# STM32U5F7 register map
File version: 1.1
CPU: CM33 r0p1, little endian, MPU, FPU, 4 interrupt priority bits
Registers are 32-bit, read-write, reset 0x0 unless marked. A register's access mark holds for its fields unless they carry their own. Offsets are from the block's base; [hi:lo] are bit positions.

## I2C1 — Inter-integrated circuit
Base 0x40005400
Same registers: I2C2 0x40005800, I2C4 0x40008400, I2C5 0x40009800, I2C6 0x40009C00, I2C3 0x46002800, SEC_I2C1 0x50005400, SEC_I2C2 0x50005800, SEC_I2C4 0x50008400, SEC_I2C5 0x50009800, SEC_I2C6 0x50009C00, SEC_I2C3 0x56002800
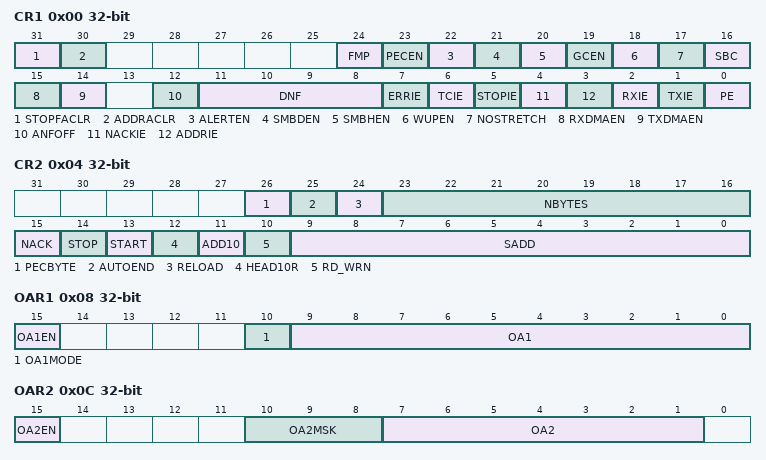
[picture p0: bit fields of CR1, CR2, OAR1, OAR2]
0x00 CR1 — Control register 1
  [31] STOPFACLR — STOP detection flag (STOPF) automatic clear
  [30] ADDRACLR — Address match flag (ADDR) automatic clear
  [24] FMP — Fast-mode Plus 20 mA drive enable
  [23] PECEN — PEC enable
  [22] ALERTEN — SMBUS alert enable
  [21] SMBDEN — SMBus Device Default address
  [20] SMBHEN — SMBus Host address enable
  [19] GCEN — General call enable
  [18] WUPEN — Wakeup from STOP enable
  [17] NOSTRETCH — Clock stretching disable
  [16] SBC — Slave byte control
  [15] RXDMAEN — DMA reception requests
  [14] TXDMAEN — DMA transmission requests
  [12] ANFOFF — Analog noise filter OFF
  [11:8] DNF — Digital noise filter
  [7] ERRIE — Error interrupts enable
  [6] TCIE — Transfer Complete interrupt
  [5] STOPIE — STOP detection Interrupt
  [4] NACKIE — Not acknowledge received interrupt
  [3] ADDRIE — Address match interrupt enable (slave
  [2] RXIE — RX Interrupt enable
  [1] TXIE — TX Interrupt enable
  [0] PE — Peripheral enable
0x04 CR2 — Control register 2
  [26] PECBYTE — Packet error checking byte
  [25] AUTOEND — Automatic end mode (master
  [24] RELOAD — NBYTES reload mode
  [23:16] NBYTES — Number of bytes
  [15] NACK — NACK generation (slave
  [14] STOP — Stop generation (master
  [13] START — Start generation
  [12] HEAD10R — 10-bit address header only read
  [11] ADD10 — 10-bit addressing mode (master
  [10] RD_WRN — Transfer direction (master
  [9:0] SADD — Slave address bit (master
0x08 OAR1 — Own address register 1
  [15] OA1EN — Own Address 1 enable
  [10] OA1MODE — Own Address 1 10-bit mode
  [9:0] OA1 — Interface address
0x0C OAR2 — Own address register 2
  [15] OA2EN — Own Address 2 enable
  [10:8] OA2MSK — Own Address 2 masks
  [7:1] OA2 — Interface address
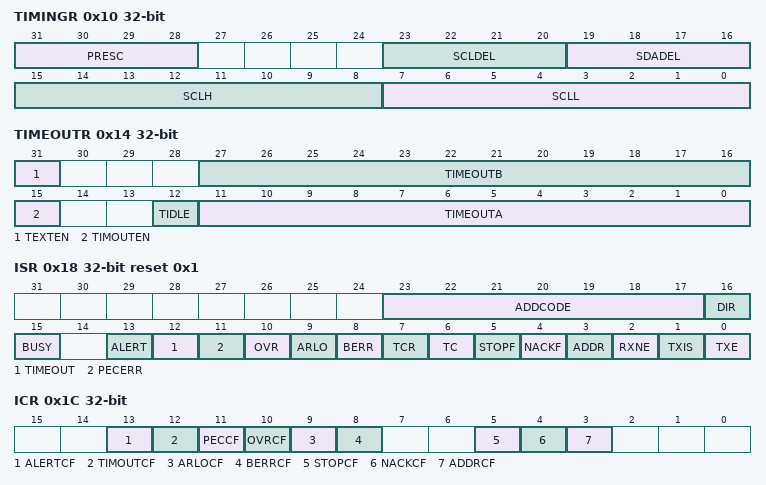
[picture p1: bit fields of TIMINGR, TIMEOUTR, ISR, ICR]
0x10 TIMINGR — Timing register
  [31:28] PRESC — Timing prescaler
  [23:20] SCLDEL — Data setup time
  [19:16] SDADEL — Data hold time
  [15:8] SCLH — SCL high period (master
  [7:0] SCLL — SCL low period (master
0x14 TIMEOUTR — Status register 1
  [31] TEXTEN — Extended clock timeout
  [27:16] TIMEOUTB — Bus timeout B
  [15] TIMOUTEN — Clock timeout enable
  [12] TIDLE — Idle clock timeout
  [11:0] TIMEOUTA — Bus timeout A
0x18 ISR access per field reset 0x1 — Interrupt and Status register
  [23:17] ADDCODE ro — Address match code (Slave
  [16] DIR ro — Transfer direction (Slave
  [15] BUSY ro — Bus busy
  [13] ALERT ro — SMBus alert
  [12] TIMEOUT ro — Timeout or t_low detection
  [11] PECERR ro — PEC Error in reception
  [10] OVR ro — Overrun/Underrun (slave
  [9] ARLO ro — Arbitration lost
  [8] BERR ro — Bus error
  [7] TCR ro — Transfer Complete Reload
  [6] TC ro — Transfer Complete (master
  [5] STOPF ro — Stop detection flag
  [4] NACKF ro — Not acknowledge received
  [3] ADDR ro — Address matched (slave
  [2] RXNE ro — Receive data register not empty
  [1] TXIS rw — Transmit interrupt status
  [0] TXE rw — Transmit data register empty
0x1C ICR wo — Interrupt clear register
  [13] ALERTCF — Alert flag clear
  [12] TIMOUTCF — Timeout detection flag
  [11] PECCF — PEC Error flag clear
  [10] OVRCF — Overrun/Underrun flag
  [9] ARLOCF — Arbitration lost flag
  [8] BERRCF — Bus error flag clear
  [5] STOPCF — Stop detection flag clear
  [4] NACKCF — Not Acknowledge flag clear
  [3] ADDRCF — Address Matched flag clear
0x20 PECR ro — PEC register
  [7:0] PEC — Packet error checking
0x24 RXDR ro — Receive data register
  [7:0] RXDATA — 8-bit receive data
0x28 TXDR — Transmit data register
  [7:0] TXDATA — 8-bit transmit data
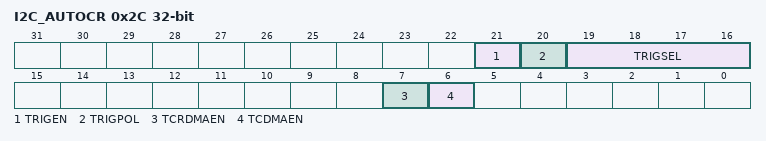
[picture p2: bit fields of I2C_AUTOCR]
0x2C I2C_AUTOCR — I2C Autonomous mode control register
  [21] TRIGEN — Trigger enable
  [20] TRIGPOL — Trigger polarity
  [19:16] TRIGSEL — Trigger selection
  [7] TCRDMAEN — DMA request enable on Transfer Complete Reload event
  [6] TCDMAEN — DMA request enable on Transfer Complete event
